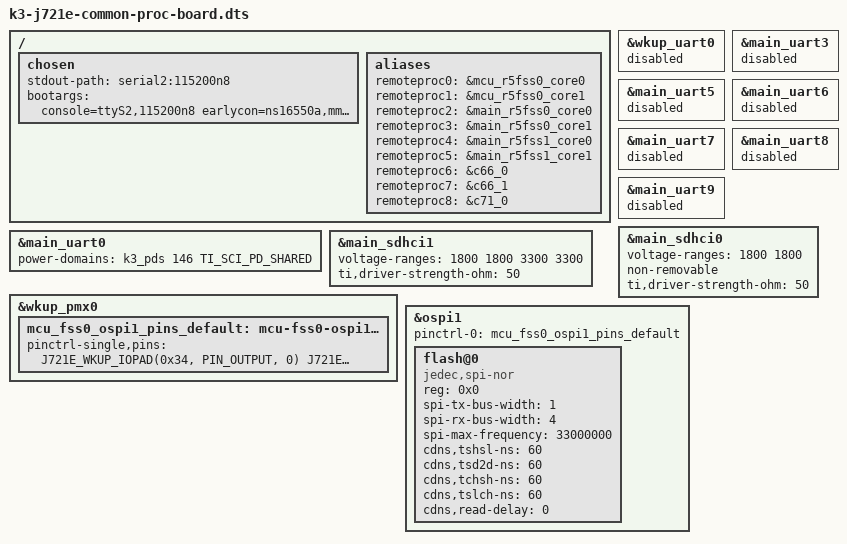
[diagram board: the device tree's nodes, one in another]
// SPDX-License-Identifier: GPL-2.0
/*
 * Copyright (C) 2019 Texas Instruments Incorporated - http://www.ti.com/
 */

/dts-v1/;

#include "k3-j721e-som-p0.dtsi"

/ {
	chosen {
		stdout-path = "serial2:115200n8";
		bootargs = "console=ttyS2,115200n8 earlycon=ns16550a,mmio32,0x02800000";
	};

	aliases {
		remoteproc0 = &mcu_r5fss0_core0;
		remoteproc1 = &mcu_r5fss0_core1;
		remoteproc2 = &main_r5fss0_core0;
		remoteproc3 = &main_r5fss0_core1;
		remoteproc4 = &main_r5fss1_core0;
		remoteproc5 = &main_r5fss1_core1;
		remoteproc6 = &c66_0;
		remoteproc7 = &c66_1;
		remoteproc8 = &c71_0;
	};
};

&wkup_uart0 {
	/* Wakeup UART is used by System firmware */
	status = "disabled";
};

&main_uart0 {
	power-domains = <&k3_pds 146 TI_SCI_PD_SHARED>;
};

&main_uart3 {
	/* UART not brought out */
	status = "disabled";
};

&main_uart5 {
	/* UART not brought out */
	status = "disabled";
};

&main_uart6 {
	/* UART not brought out */
	status = "disabled";
};

&main_uart7 {
	/* UART not brought out */
	status = "disabled";
};

&main_uart8 {
	/* UART not brought out */
	status = "disabled";
};

&main_uart9 {
	/* UART not brought out */
	status = "disabled";
};

&main_sdhci0 {
	/* eMMC */
	voltage-ranges = <1800 1800>;
	non-removable;
	ti,driver-strength-ohm = <50>;
};

&main_sdhci1 {
	/* SD/MMC */
	voltage-ranges = <1800 1800 3300 3300>;
	ti,driver-strength-ohm = <50>;
};


&wkup_pmx0 {
	mcu_fss0_ospi1_pins_default: mcu-fss0-ospi1-pins-default {
		pinctrl-single,pins = <
			J721E_WKUP_IOPAD(0x34, PIN_OUTPUT, 0) /* (F22) MCU_OSPI1_CLK */
			J721E_WKUP_IOPAD(0x50, PIN_OUTPUT, 0) /* (C22) MCU_OSPI1_CSn0 */
			J721E_WKUP_IOPAD(0x40, PIN_INPUT, 0) /* (D22) MCU_OSPI1_D0 */
			J721E_WKUP_IOPAD(0x44, PIN_INPUT, 0) /* (G22) MCU_OSPI1_D1 */
			J721E_WKUP_IOPAD(0x48, PIN_INPUT, 0) /* (D23) MCU_OSPI1_D2 */
			J721E_WKUP_IOPAD(0x4c, PIN_INPUT, 0) /* (C23) MCU_OSPI1_D3 */
			J721E_WKUP_IOPAD(0x3c, PIN_INPUT, 0) /* (B23) MCU_OSPI1_DQS */
			J721E_WKUP_IOPAD(0x38, PIN_INPUT, 0) /* (A23) MCU_OSPI1_LBCLKO */
		>;
	};
};

&ospi1 {
	pinctrl-names = "default";
	pinctrl-0 = <&mcu_fss0_ospi1_pins_default>;

	flash@0{
		compatible = "jedec,spi-nor";
		reg = <0x0>;
		spi-tx-bus-width = <1>;
		spi-rx-bus-width = <4>;
		spi-max-frequency = <33000000>;
		cdns,tshsl-ns = <60>;
		cdns,tsd2d-ns = <60>;
		cdns,tchsh-ns = <60>;
		cdns,tslch-ns = <60>;
		cdns,read-delay = <0>;
		#address-cells = <1>;
		#size-cells = <1>;
	};
};
